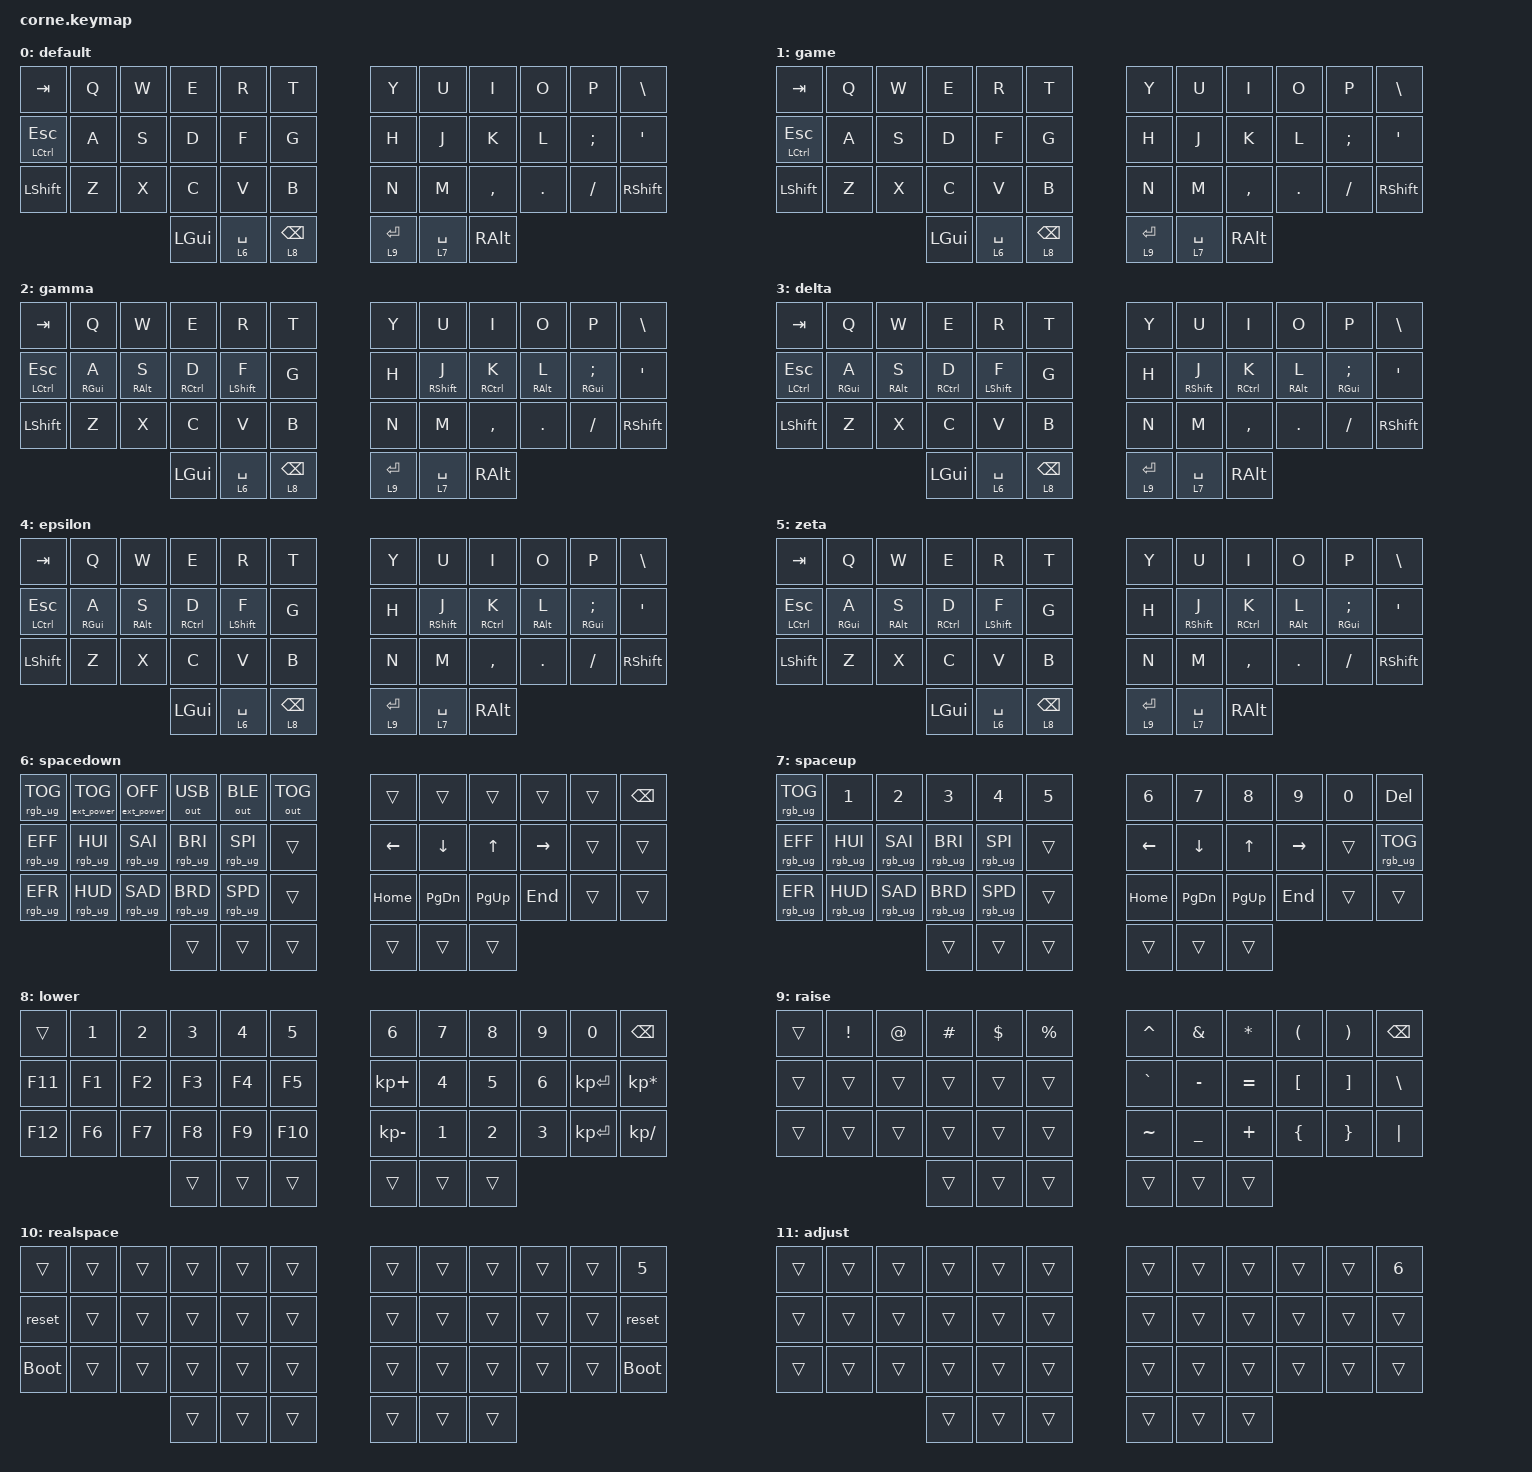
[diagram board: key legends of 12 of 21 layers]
/*
 * Copyright (c) 2020-2022 The ZMK Contributors
 *
 * SPDX-License-Identifier: MIT
 */

#include <behaviors.dtsi>

// #include <dt-bindings/zmk/mouse.h>

#include <dt-bindings/led/led.h>
#include <dt-bindings/zmk/keys.h>
#include <dt-bindings/zmk/rgb.h>
#include <dt-bindings/zmk/ext_power.h>
#include <dt-bindings/zmk/outputs.h>
#include <dt-bindings/zmk/bt.h>

#define _DF  0
#define _GM  1
#define _GA  2
#define _DE  3
#define _EP  4
#define _ZE  5
#define _SD  6
#define _SU  7
#define _LW  8
#define _RE  9
#define _RS 10
#define _AJ 11
#define _SS 12
#define _HS 13
#define _SL 14
#define _FS 15
#define _KS 16
#define _CS 17
#define _BH 18
#define _WH 19
#define _WP 20

&spi1 {
    compatible = "nordic,nrf-spim";

    /* Cannot be used together with i2c0. */

    status = "okay";
    mosi-pin = <6>;

    // Unused pins, needed for SPI definition, but not used by the ws2812 driver itself.

    sck-pin = <5>;
    miso-pin = <7>;

    led_strip: ws2812@0 {
        compatible = "worldsemi,ws2812-spi";
        label = "SK6812mini";

        /* SPI */

        reg = <0>;/* ignored, but necessary for SPI bindings */
        spi-max-frequency = <4000000>;

        /* WS2812 */

        chain-length = <27>;/* There are per-key RGB, but the first 6 are underglow */
        spi-one-frame = <0x70>;
        spi-zero-frame = <0x40>;
        color-mapping = <LED_COLOR_ID_GREEN LED_COLOR_ID_RED LED_COLOR_ID_BLUE>;
    };
};

/ {
    chosen {
        zmk,underglow = &led_strip;
    };

    behaviors {
        lt: behavior_layer_tap {
            quick-tap-ms = <180>;
        };
        mt: behavior_mod_tap {
            tapping-term-ms = <180>;
        };
    };

    conditional_layers {
        compatible = "zmk,conditional-layers";

        realspace_layer {
            if-layers = <_SU _SD>;
            then-layer = <_RS>;
        };

        adjust_layer {
            if-layers = <_LW _RE>;
            then-layer = <_AJ>;
        };

        subspace_layer {
            if-layers = <_SD _LW>;
            then-layer = <_SS>;
        };

        hyperspace_layer {
            if-layers = <_SU _RE>;
            then-layer = <_HS>;
        };

        slipspace_layer {
            if-layers = <_SD _RE>;
            then-layer = <_SL>;
        };

        foldspace_layer {
            if-layers = <_SU _LW>;
            then-layer = <_FS>;
        };

        knownspace_layer {
            if-layers = <_LW _RS>;
            then-layer = <_KS>;
        };

        cyberspace_layer {
            if-layers = <_RE _RS>;
            then-layer = <_CS>;
        };

        blackhole_layer {
            if-layers = <_SD _AJ>;
            then-layer = <_BH>;
        };

        wormhole_layer {
            if-layers = <_SU _AJ>;
            then-layer = <_WH>;
        };

        warp_layer {
            if-layers = <_RS _AJ>;
            then-layer = <_WP>;
        };
    };

    keymap {
        compatible = "zmk,keymap";

        default_layer {
            label = "default";
            bindings = <
      &kp TAB  &kp Q  &kp W     &kp E        &kp R       &kp T        &kp Y        &kp U      &kp I    &kp O     &kp P   &kp BSLH
&mt LCTRL ESC  &kp A  &kp S     &kp D        &kp F       &kp G        &kp H        &kp J      &kp K    &kp L  &kp SEMI    &kp SQT
    &kp LSHFT  &kp Z  &kp X     &kp C        &kp V       &kp B        &kp N        &kp M  &kp COMMA  &kp DOT  &kp FSLH  &kp RSHFT
                             &kp LGUI  &lt 6 SPACE  &lt 8 BSPC    &lt 9 RET  &lt 7 SPACE   &kp RALT
            >;
        };

        game_layer {
            label = "game";
            bindings = <
      &kp TAB  &kp Q  &kp W     &kp E        &kp R       &kp T        &kp Y        &kp U      &kp I    &kp O     &kp P   &kp BSLH
&mt LCTRL ESC  &kp A  &kp S     &kp D        &kp F       &kp G        &kp H        &kp J      &kp K    &kp L  &kp SEMI    &kp SQT
    &kp LSHFT  &kp Z  &kp X     &kp C        &kp V       &kp B        &kp N        &kp M  &kp COMMA  &kp DOT  &kp FSLH  &kp RSHFT
                             &kp LGUI  &lt 6 SPACE  &lt 8 BSPC    &lt 9 RET  &lt 7 SPACE   &kp RALT
            >;
        };

        gamma_layer {
            label = "gamma";
            bindings = <
      &kp TAB       &kp Q       &kp W        &kp E        &kp R       &kp T        &kp Y        &kp U        &kp I       &kp O          &kp P   &kp BSLH
&mt LCTRL ESC  &mt RGUI A  &mt RALT S  &mt RCTRL D  &mt LSHFT F       &kp G        &kp H  &mt RSHFT J  &mt RCTRL K  &mt RALT L  &mt RGUI SEMI    &kp SQT
    &kp LSHFT       &kp Z       &kp X        &kp C        &kp V       &kp B        &kp N        &kp M    &kp COMMA     &kp DOT       &kp FSLH  &kp RSHFT
                                          &kp LGUI  &lt 6 SPACE  &lt 8 BSPC    &lt 9 RET  &lt 7 SPACE     &kp RALT
            >;
        };

        delta_layer {
            label = "delta";
            bindings = <
      &kp TAB       &kp Q       &kp W        &kp E        &kp R       &kp T        &kp Y        &kp U        &kp I       &kp O          &kp P   &kp BSLH
&mt LCTRL ESC  &mt RGUI A  &mt RALT S  &mt RCTRL D  &mt LSHFT F       &kp G        &kp H  &mt RSHFT J  &mt RCTRL K  &mt RALT L  &mt RGUI SEMI    &kp SQT
    &kp LSHFT       &kp Z       &kp X        &kp C        &kp V       &kp B        &kp N        &kp M    &kp COMMA     &kp DOT       &kp FSLH  &kp RSHFT
                                          &kp LGUI  &lt 6 SPACE  &lt 8 BSPC    &lt 9 RET  &lt 7 SPACE     &kp RALT
            >;
        };

        epsilon_layer {
            label = "epsilon";
            bindings = <
      &kp TAB       &kp Q       &kp W        &kp E        &kp R       &kp T        &kp Y        &kp U        &kp I       &kp O          &kp P   &kp BSLH
&mt LCTRL ESC  &mt RGUI A  &mt RALT S  &mt RCTRL D  &mt LSHFT F       &kp G        &kp H  &mt RSHFT J  &mt RCTRL K  &mt RALT L  &mt RGUI SEMI    &kp SQT
    &kp LSHFT       &kp Z       &kp X        &kp C        &kp V       &kp B        &kp N        &kp M    &kp COMMA     &kp DOT       &kp FSLH  &kp RSHFT
                                          &kp LGUI  &lt 6 SPACE  &lt 8 BSPC    &lt 9 RET  &lt 7 SPACE     &kp RALT
            >;
        };

        zeta_layer {
            label = "zeta";
            bindings = <
      &kp TAB       &kp Q       &kp W        &kp E        &kp R       &kp T        &kp Y        &kp U        &kp I       &kp O          &kp P   &kp BSLH
&mt LCTRL ESC  &mt RGUI A  &mt RALT S  &mt RCTRL D  &mt LSHFT F       &kp G        &kp H  &mt RSHFT J  &mt RCTRL K  &mt RALT L  &mt RGUI SEMI    &kp SQT
    &kp LSHFT       &kp Z       &kp X        &kp C        &kp V       &kp B        &kp N        &kp M    &kp COMMA     &kp DOT       &kp FSLH  &kp RSHFT
                                          &kp LGUI  &lt 6 SPACE  &lt 8 BSPC    &lt 9 RET  &lt 7 SPACE     &kp RALT
            >;
        };

        spacedown_layer {
            label = "spacedown";
            bindings = <
&rgb_ug RGB_TOG  &ext_power EP_TOG  &ext_power EP_OFF     &out OUT_USB     &out OUT_BLE  &out OUT_TOG      &trans     &trans     &trans     &trans  &trans  &kp BSPC
&rgb_ug RGB_EFF    &rgb_ug RGB_HUI    &rgb_ug RGB_SAI  &rgb_ug RGB_BRI  &rgb_ug RGB_SPI        &trans    &kp LEFT   &kp DOWN     &kp UP  &kp RIGHT  &trans    &trans
&rgb_ug RGB_EFR    &rgb_ug RGB_HUD    &rgb_ug RGB_SAD  &rgb_ug RGB_BRD  &rgb_ug RGB_SPD        &trans    &kp HOME  &kp PG_DN  &kp PG_UP    &kp END  &trans    &trans
                                                                &trans           &trans        &trans      &trans     &trans     &trans
            >;
        };

        spaceup_layer {
            label = "spaceup";
            bindings = <
&rgb_ug RGB_TOG           &kp N1           &kp N2           &kp N3           &kp N4  &kp N5      &kp N6     &kp N7     &kp N8     &kp N9  &kp N0          &kp DEL
&rgb_ug RGB_EFF  &rgb_ug RGB_HUI  &rgb_ug RGB_SAI  &rgb_ug RGB_BRI  &rgb_ug RGB_SPI  &trans    &kp LEFT   &kp DOWN     &kp UP  &kp RIGHT  &trans  &rgb_ug RGB_TOG
&rgb_ug RGB_EFR  &rgb_ug RGB_HUD  &rgb_ug RGB_SAD  &rgb_ug RGB_BRD  &rgb_ug RGB_SPD  &trans    &kp HOME  &kp PG_DN  &kp PG_UP    &kp END  &trans           &trans
                                                            &trans           &trans  &trans      &trans     &trans     &trans
            >;
        };

        lower_layer {
            label = "lower";
            bindings = <
 &trans  &kp N1  &kp N2  &kp N3  &kp N4   &kp N5          &kp N6  &kp N7  &kp N8  &kp N9        &kp N0         &kp BSPC
&kp F11  &kp F1  &kp F2  &kp F3  &kp F4   &kp F5     &kp KP_PLUS  &kp N4  &kp N5  &kp N6  &kp KP_ENTER  &kp KP_MULTIPLY
&kp F12  &kp F6  &kp F7  &kp F8  &kp F9  &kp F10    &kp KP_MINUS  &kp N1  &kp N2  &kp N3  &kp KP_ENTER    &kp KP_DIVIDE
                         &trans  &trans   &trans          &trans  &trans  &trans
            >;
        };

        raise_layer {
            label = "raise";
            bindings = <
&trans  &kp EXCL  &kp AT  &kp HASH  &kp DLLR  &kp PRCNT    &kp CARET   &kp AMPS  &kp ASTRK  &kp LPAR  &kp RPAR  &kp BSPC
&trans    &trans  &trans    &trans    &trans     &trans    &kp GRAVE  &kp MINUS  &kp EQUAL  &kp LBKT  &kp RBKT  &kp BSLH
&trans    &trans  &trans    &trans    &trans     &trans    &kp TILDE  &kp UNDER   &kp PLUS  &kp LBRC  &kp RBRC  &kp PIPE
                            &trans    &trans     &trans       &trans     &trans     &trans
            >;
        };

        realspace_layer {
            label = "realspace";
            bindings = <
     &trans  &trans  &trans  &trans  &trans  &trans    &trans  &trans  &trans  &trans  &trans       &kp N5
     &reset  &trans  &trans  &trans  &trans  &trans    &trans  &trans  &trans  &trans  &trans       &reset
&bootloader  &trans  &trans  &trans  &trans  &trans    &trans  &trans  &trans  &trans  &trans  &bootloader
                             &trans  &trans  &trans    &trans  &trans  &trans
            >;
        };

        adjust_layer {
            label = "adjust";
            bindings = <
&trans  &trans  &trans  &trans  &trans  &trans    &trans  &trans  &trans  &trans  &trans  &kp N6
&trans  &trans  &trans  &trans  &trans  &trans    &trans  &trans  &trans  &trans  &trans  &trans
&trans  &trans  &trans  &trans  &trans  &trans    &trans  &trans  &trans  &trans  &trans  &trans
                        &trans  &trans  &trans    &trans  &trans  &trans
            >;
        };

        subspace_layer {
            label = "subspace";
            bindings = <
&rgb_ug RGB_TOG        &trans        &trans  &out OUT_USB  &out OUT_BLE  &out OUT_TOG    &trans  &trans  &trans  &trans  &trans  &kp N7
     &bt BT_CLR  &bt BT_SEL 0  &bt BT_SEL 1  &bt BT_SEL 2  &bt BT_SEL 3  &bt BT_SEL 4    &trans  &trans  &trans  &trans  &trans  &trans
         &trans  &bt BT_SEL 5  &bt BT_SEL 6  &bt BT_SEL 7  &bt BT_SEL 8  &bt BT_SEL 9    &trans  &trans  &trans  &trans  &trans  &trans
                                                   &trans        &trans        &trans    &trans  &trans  &trans
            >;
        };

        hyperspace_layer {
            label = "hyperspace";
            bindings = <
&rgb_ug RGB_TOG           &trans           &trans           &trans           &trans  &trans      &trans     &trans     &trans     &trans  &trans  &kp N8
&rgb_ug RGB_EFF  &rgb_ug RGB_HUI  &rgb_ug RGB_SAI  &rgb_ug RGB_BRI  &rgb_ug RGB_SPI  &trans    &kp LEFT   &kp DOWN     &kp UP  &kp RIGHT  &trans  &trans
&rgb_ug RGB_EFR  &rgb_ug RGB_HUD  &rgb_ug RGB_SAD  &rgb_ug RGB_BRD  &rgb_ug RGB_SPD  &trans    &kp HOME  &kp PG_DN  &kp PG_UP    &kp END  &trans  &trans
                                                            &trans           &trans  &trans      &trans     &trans     &trans
            >;
        };

        slipspace_layer {
            label = "slipspace";
            bindings = <
&trans  &trans  &trans  &trans  &trans  &trans    &trans  &trans  &trans  &trans  &trans  &trans
&trans  &trans  &trans  &trans  &trans  &trans    &trans  &trans  &trans  &trans  &trans  &trans
&trans  &trans  &trans  &trans  &trans  &trans    &trans  &trans  &trans  &trans  &trans  &trans
                        &trans  &trans  &trans    &trans  &trans  &trans
            >;
        };

        foldspace_layer {
            label = "foldspace";
            bindings = <
&trans  &trans  &trans  &trans  &trans  &trans    &trans  &trans  &trans  &trans  &trans  &trans
&trans  &trans  &trans  &trans  &trans  &trans    &trans  &trans  &trans  &trans  &trans  &trans
&trans  &trans  &trans  &trans  &trans  &trans    &trans  &trans  &trans  &trans  &trans  &trans
                        &trans  &trans  &trans    &trans  &trans  &trans
            >;
        };

        knownspace_layer {
            label = "knownspace";
            bindings = <
&trans  &trans  &trans  &trans  &trans  &trans    &trans  &trans  &trans  &trans  &trans  &trans
&trans  &trans  &trans  &trans  &trans  &trans    &trans  &trans  &trans  &trans  &trans  &trans
&trans  &trans  &trans  &trans  &trans  &trans    &trans  &trans  &trans  &trans  &trans  &trans
                        &trans  &trans  &trans    &trans  &trans  &trans
            >;
        };

        cyberspace_layer {
            label = "cyberspace";
            bindings = <
&trans  &trans  &trans  &trans  &trans  &trans    &trans  &trans  &trans  &trans  &trans  &trans
&trans  &trans  &trans  &trans  &trans  &trans    &trans  &trans  &trans  &trans  &trans  &trans
&trans  &trans  &trans  &trans  &trans  &trans    &trans  &trans  &trans  &trans  &trans  &trans
                        &trans  &trans  &trans    &trans  &trans  &trans
            >;
        };

        blackhole_layer {
            label = "blackhole";
            bindings = <
&trans  &trans  &trans  &trans  &trans  &trans    &trans  &trans  &trans  &trans  &trans  &trans
&trans  &trans  &trans  &trans  &trans  &trans    &trans  &trans  &trans  &trans  &trans  &trans
&trans  &trans  &trans  &trans  &trans  &trans    &trans  &trans  &trans  &trans  &trans  &trans
                        &trans  &trans  &trans    &trans  &trans  &trans
            >;
        };

        wormhole_layer {
            label = "wormhole";
            bindings = <
&trans  &trans  &trans  &trans  &trans  &trans    &trans  &trans  &trans  &trans  &trans  &trans
&trans  &trans  &trans  &trans  &trans  &trans    &trans  &trans  &trans  &trans  &trans  &trans
&trans  &trans  &trans  &trans  &trans  &trans    &trans  &trans  &trans  &trans  &trans  &trans
                        &trans  &trans  &trans    &trans  &trans  &trans
            >;
        };

        warp_layer {
            label = "warp";
            bindings = <
     &trans  &trans  &trans  &trans  &trans  &trans    &trans  &trans  &trans  &trans  &trans       &trans
&bootloader  &trans  &trans  &trans  &trans  &trans    &trans  &trans  &trans  &trans  &trans  &bootloader
     &reset  &trans  &trans  &trans  &trans  &trans    &trans  &trans  &trans  &trans  &trans       &reset
                             &trans  &trans  &trans    &trans  &trans  &trans
            >;
        };
    };
};
